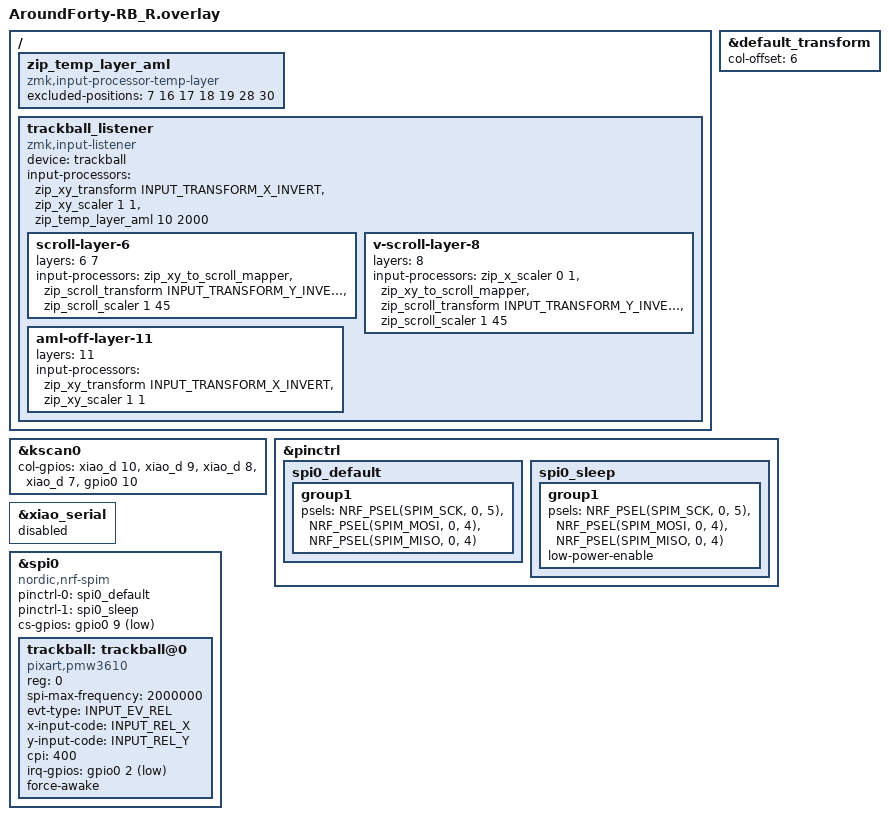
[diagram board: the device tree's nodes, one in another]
#include "AroundForty-RB.dtsi"
#include <dt-bindings/zmk/pointing.h>
#include <dt-bindings/zmk/input_transform.h>
#include <input/processors.dtsi>
#include <zephyr/dt-bindings/input/input-event-codes.h>
#include <zephyr/dt-bindings/pinctrl/nrf-pinctrl.h>

&default_transform {
    col-offset = <6>;
};

&kscan0 {
    col-gpios
        = <&xiao_d 10 GPIO_ACTIVE_HIGH>
        , <&xiao_d  9 GPIO_ACTIVE_HIGH>
        , <&xiao_d  8 GPIO_ACTIVE_HIGH>
        , <&xiao_d  7 GPIO_ACTIVE_HIGH>
        , <&gpio0  10 GPIO_ACTIVE_HIGH>
        ;
};

/ {
    /* AML用 temp_layer: excluded-positions のキーのみレイヤー維持、それ以外で解除 */
    zip_temp_layer_aml: zip_temp_layer_aml {
        compatible = "zmk,input-processor-temp-layer";
        #input-processor-cells = <2>;
        excluded-positions = <7 16 17 18 19 28 30>;
    };

    trackball_listener: trackball_listener {
        compatible = "zmk,input-listener";
        device = <&trackball>;
        // base: X反転 → スケール → AML自動発動（レイヤー10へ一時切替、2000ms）
        input-processors = <&zip_xy_transform INPUT_TRANSFORM_X_INVERT>,
                           <&zip_xy_scaler 1 1>,
                           <&zip_temp_layer_aml 10 2000>;

        // レイヤー6/7（通常の全方向スクロール）← 先に評価されるよう上に配置
        scroll-layer-6 {
            layers = <6 7>;
            input-processors = <&zip_xy_to_scroll_mapper>,
                               <&zip_scroll_transform INPUT_TRANSFORM_Y_INVERT>,
                               <&zip_scroll_scaler 1 45>;
        };

        // レイヤー8（垂直スクロール専用）
        v-scroll-layer-8 {
            layers = <8>;
            // スクロール変換の前に「&zip_x_scaler 0 1」を挟んでX軸の入力を0にする
            input-processors = <&zip_x_scaler 0 1>,
                               <&zip_xy_to_scroll_mapper>,
                               <&zip_scroll_transform INPUT_TRANSFORM_Y_INVERT>,
                               <&zip_scroll_scaler 1 45>;
        };

        // レイヤー11（AML-Off フラグ）がONのとき: AML自動発動をスキップして通常カーソル
        // ※スクロール系（6/7/8）が先にマッチするので、スクロールはAML-Off中でも有効
        aml-off-layer-11 {
            layers = <11>;
            input-processors = <&zip_xy_transform INPUT_TRANSFORM_X_INVERT>,
                               <&zip_xy_scaler 1 1>;
        };
    };
};

&pinctrl {
    spi0_default: spi0_default {
        group1 {
            psels = <NRF_PSEL(SPIM_SCK,  0, 5)>,
                    <NRF_PSEL(SPIM_MOSI, 0, 4)>,
                    <NRF_PSEL(SPIM_MISO, 0, 4)>;
        };
    };

    spi0_sleep: spi0_sleep {
        group1 {
            psels = <NRF_PSEL(SPIM_SCK,  0, 5)>,
                    <NRF_PSEL(SPIM_MOSI, 0, 4)>,
                    <NRF_PSEL(SPIM_MISO, 0, 4)>;
            low-power-enable;
        };
    };
};

&xiao_serial { status = "disabled"; };

&spi0 {
    status = "okay";
    compatible = "nordic,nrf-spim";
    pinctrl-0 = <&spi0_default>;
    pinctrl-1 = <&spi0_sleep>;
    pinctrl-names = "default", "sleep";
    cs-gpios = <&gpio0 9 GPIO_ACTIVE_LOW>;

    trackball: trackball@0 {
        status = "okay";
        compatible = "pixart,pmw3610";
        reg = <0>;
        spi-max-frequency = <2000000>;
        evt-type = <INPUT_EV_REL>;
        x-input-code = <INPUT_REL_X>;
        y-input-code = <INPUT_REL_Y>;
        cpi = <400>;
        irq-gpios = <&gpio0 2 (GPIO_ACTIVE_LOW | GPIO_PULL_UP)>;
        force-awake;
    };
};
